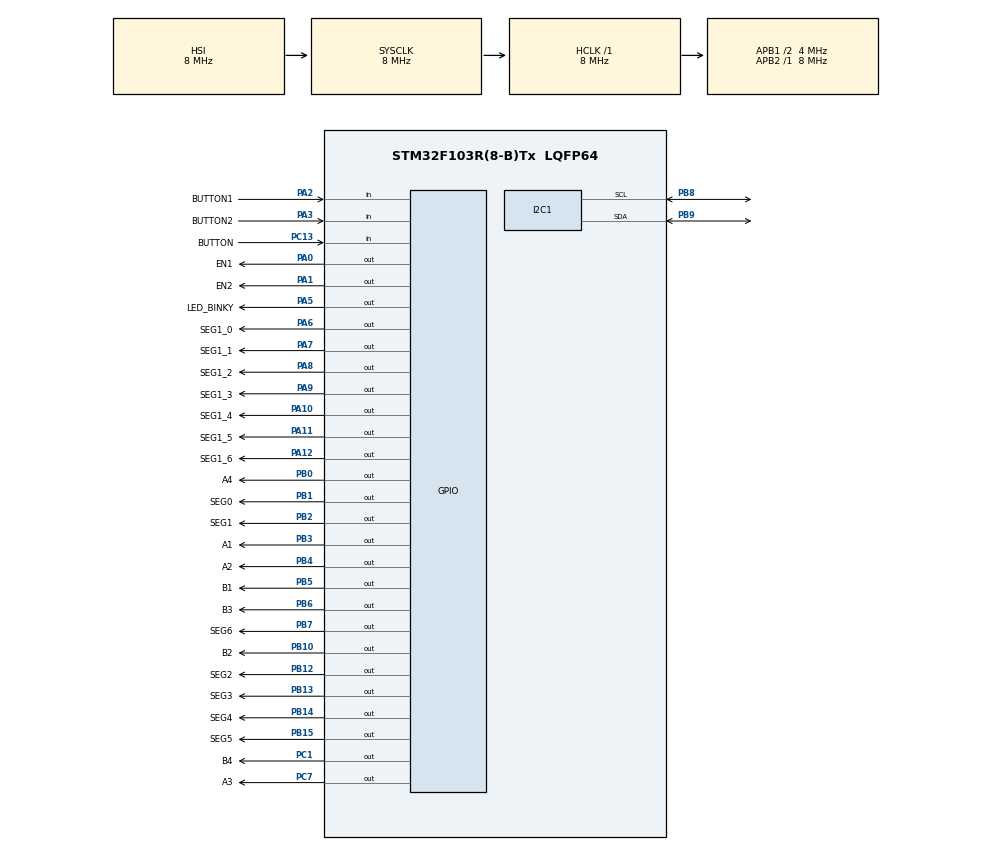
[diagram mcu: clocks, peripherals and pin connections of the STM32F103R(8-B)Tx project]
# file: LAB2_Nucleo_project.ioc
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Mcu.Family=STM32F1
Mcu.Name=STM32F103R(8-B)Tx
Mcu.Package=LQFP64
NVIC.I2C1_ER_IRQn=true\:0\:0\:false\:false\:true\:true\:true
NVIC.I2C1_EV_IRQn=true\:0\:0\:false\:false\:true\:true\:true
NVIC.PriorityGroup=NVIC_PRIORITYGROUP_4
NVIC.TIM2_IRQn=true\:0\:0\:false\:false\:true\:true\:true
PA0-WKUP.GPIO_Label=EN1
PA0-WKUP.Signal=GPIO_Output
PA1.GPIO_Label=EN2
PA1.Signal=GPIO_Output
PA10.GPIO_Label=SEG1_4
PA10.Signal=GPIO_Output
PA11.GPIO_Label=SEG1_5
PA11.Signal=GPIO_Output
PA12.GPIO_Label=SEG1_6
PA12.Signal=GPIO_Output
PA13.Mode=Serial_Wire
PA13.Signal=SYS_JTMS-SWDIO
PA14.Mode=Serial_Wire
PA14.Signal=SYS_JTCK-SWCLK
PA2.GPIO_Label=BUTTON1
PA2.GPIO_PuPd=GPIO_PULLUP
PA2.Signal=GPIO_Input
PA3.GPIO_Label=BUTTON2
PA3.GPIO_PuPd=GPIO_PULLUP
PA3.Signal=GPIO_Input
PA5.GPIO_Label=LED_BINKY
PA5.Signal=GPIO_Output
PA6.GPIO_Label=SEG1_0
PA6.Signal=GPIO_Output
PA7.GPIO_Label=SEG1_1
PA7.Signal=GPIO_Output
PA8.GPIO_Label=SEG1_2
PA8.Signal=GPIO_Output
PA9.GPIO_Label=SEG1_3
PA9.Signal=GPIO_Output
PB0.GPIO_Label=A4
PB0.Signal=GPIO_Output
PB1.GPIO_Label=SEG0
PB1.Signal=GPIO_Output
PB10.GPIO_Label=B2
PB10.Signal=GPIO_Output
PB12.GPIO_Label=SEG2
PB12.Signal=GPIO_Output
PB13.GPIO_Label=SEG3
PB13.Signal=GPIO_Output
PB14.GPIO_Label=SEG4
PB14.Signal=GPIO_Output
PB15.GPIO_Label=SEG5
PB15.Signal=GPIO_Output
PB2.GPIO_Label=SEG1
PB2.Signal=GPIO_Output
PB3.GPIO_Label=A1
PB3.Signal=GPIO_Output
PB4.GPIO_Label=A2
PB4.Signal=GPIO_Output
PB5.GPIO_Label=B1
PB5.Signal=GPIO_Output
PB6.GPIO_Label=B3
PB6.Signal=GPIO_Output
PB7.GPIO_Label=SEG6
PB7.Signal=GPIO_Output
PB8.Mode=I2C
PB8.Signal=I2C1_SCL
PB9.Mode=I2C
PB9.Signal=I2C1_SDA
PC1.GPIO_Label=B4
PC1.Signal=GPIO_Output
PC13-TAMPER-RTC.GPIO_Label=BUTTON
PC13-TAMPER-RTC.GPIO_PuPd=GPIO_PULLUP
PC13-TAMPER-RTC.Signal=GPIO_Input
PC14-OSC32_IN.Mode=LSE-External-Oscillator
PC14-OSC32_IN.Signal=RCC_OSC32_IN
PC15-OSC32_OUT.Mode=LSE-External-Oscillator
PC15-OSC32_OUT.Signal=RCC_OSC32_OUT
PC7.GPIO_Label=A3
PC7.Signal=GPIO_Output
PD0-OSC_IN.Mode=HSE-External-Clock-Source
PD0-OSC_IN.Signal=RCC_OSC_IN
PD1-OSC_OUT.Mode=HSE-External-Clock-Source
PD1-OSC_OUT.Signal=RCC_OSC_OUT
ProjectManager.HeapSize=0x200
ProjectManager.StackSize=0x400
ProjectManager.TargetToolchain=STM32CubeIDE
RCC.AHBFreq_Value=8000000
RCC.APB1CLKDivider=RCC_HCLK_DIV2
RCC.APB1Freq_Value=4000000
RCC.APB1TimFreq_Value=8000000
RCC.APB2Freq_Value=8000000
RCC.APB2TimFreq_Value=8000000
RCC.HCLKFreq_Value=8000000
RCC.PLLMUL=RCC_PLL_MUL16
RCC.RTCClockSelection=RCC_RTCCLKSOURCE_LSE
RCC.SYSCLKFreq_VALUE=8000000
RCC.USBFreq_Value=64000000
TIM2.Period=9
TIM2.Prescaler=7999
VP_TIM2_VS_ClockSourceINT.Mode=Internal
board=NUCLEO-F103RB

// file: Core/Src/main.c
/* USER CODE BEGIN Header */
/**
  ******************************************************************************
  * @file           : main.c
  * @brief          : Main program body
  ******************************************************************************
  * @attention
  *
  * <h2><center>&copy; Copyright (c) 2024 STMicroelectronics.
  * All rights reserved.</center></h2>
  *
  * This software component is licensed by ST under BSD 3-Clause license,
  * the "License"; You may not use this file except in compliance with the
  * License. You may obtain a copy of the License at:
  *                        opensource.org/licenses/BSD-3-Clause
  *
  ******************************************************************************
  */
/* USER CODE END Header */
#include "main.h"

/* USER CODE BEGIN Includes */
#include "global.h"
#include "two_way_traffic.h"
#include "led7.h"
/* USER CODE END Includes */

I2C_HandleTypeDef hi2c1;

TIM_HandleTypeDef htim2;

void SystemClock_Config(void);
static void MX_GPIO_Init(void);
static void MX_TIM2_Init(void);
static void MX_I2C1_Init(void);

/* USER CODE BEGIN 0 */
GPIO_TypeDef* GPIOx[3] = {BUTTON_GPIO_Port,BUTTON1_GPIO_Port,BUTTON2_GPIO_Port};
uint16_t GPIO_Pin[3] = {BUTTON_Pin,BUTTON1_Pin,BUTTON2_Pin};
/* USER CODE END 0 */

int main(void)
{

  /* MCU Configuration--------------------------------------------------------*/

  /* Reset of all peripherals, Initializes the Flash interface and the Systick. */
  HAL_Init();

  /* Configure the system clock */
  SystemClock_Config();

  /* Initialize all configured peripherals */
  MX_GPIO_Init();
  MX_TIM2_Init();
  MX_I2C1_Init();
  /* USER CODE BEGIN 2 */
  HAL_TIM_Base_Start_IT(&htim2);
	two_way_traffic_init();
  /* USER CODE END 2 */

  /* Infinite loop */
  /* USER CODE BEGIN WHILE */
  while (1)
  {
	  two_way_traffic_run();

    /* USER CODE END WHILE */

  }
}

void SystemClock_Config(void)
{
  RCC_OscInitTypeDef RCC_OscInitStruct = {0};
  RCC_ClkInitTypeDef RCC_ClkInitStruct = {0};

  /** Initializes the RCC Oscillators according to the specified parameters
  * in the RCC_OscInitTypeDef structure.
  */
  RCC_OscInitStruct.OscillatorType = RCC_OSCILLATORTYPE_HSI;
  RCC_OscInitStruct.HSIState = RCC_HSI_ON;
  RCC_OscInitStruct.HSICalibrationValue = RCC_HSICALIBRATION_DEFAULT;
  RCC_OscInitStruct.PLL.PLLState = RCC_PLL_NONE;
  if (HAL_RCC_OscConfig(&RCC_OscInitStruct) != HAL_OK)
  {
    Error_Handler();
  }
  /** Initializes the CPU, AHB and APB buses clocks
  */
  RCC_ClkInitStruct.ClockType = RCC_CLOCKTYPE_HCLK|RCC_CLOCKTYPE_SYSCLK
                              |RCC_CLOCKTYPE_PCLK1|RCC_CLOCKTYPE_PCLK2;
  RCC_ClkInitStruct.SYSCLKSource = RCC_SYSCLKSOURCE_HSI;
  RCC_ClkInitStruct.AHBCLKDivider = RCC_SYSCLK_DIV1;
  RCC_ClkInitStruct.APB1CLKDivider = RCC_HCLK_DIV2;
  RCC_ClkInitStruct.APB2CLKDivider = RCC_HCLK_DIV1;

  if (HAL_RCC_ClockConfig(&RCC_ClkInitStruct, FLASH_LATENCY_0) != HAL_OK)
  {
    Error_Handler();
  }
}

static void MX_I2C1_Init(void)
{

  hi2c1.Instance = I2C1;
  hi2c1.Init.ClockSpeed = 100000;
  hi2c1.Init.DutyCycle = I2C_DUTYCYCLE_2;
  hi2c1.Init.OwnAddress1 = 0;
  hi2c1.Init.AddressingMode = I2C_ADDRESSINGMODE_7BIT;
  hi2c1.Init.DualAddressMode = I2C_DUALADDRESS_DISABLE;
  hi2c1.Init.OwnAddress2 = 0;
  hi2c1.Init.GeneralCallMode = I2C_GENERALCALL_DISABLE;
  hi2c1.Init.NoStretchMode = I2C_NOSTRETCH_DISABLE;
  if (HAL_I2C_Init(&hi2c1) != HAL_OK)
  {
    Error_Handler();
  }

}

static void MX_TIM2_Init(void)
{

  TIM_ClockConfigTypeDef sClockSourceConfig = {0};
  TIM_MasterConfigTypeDef sMasterConfig = {0};

  htim2.Instance = TIM2;
  htim2.Init.Prescaler = 7999;
  htim2.Init.CounterMode = TIM_COUNTERMODE_UP;
  htim2.Init.Period = 9;
  htim2.Init.ClockDivision = TIM_CLOCKDIVISION_DIV1;
  htim2.Init.AutoReloadPreload = TIM_AUTORELOAD_PRELOAD_DISABLE;
  if (HAL_TIM_Base_Init(&htim2) != HAL_OK)
  {
    Error_Handler();
  }
  sClockSourceConfig.ClockSource = TIM_CLOCKSOURCE_INTERNAL;
  if (HAL_TIM_ConfigClockSource(&htim2, &sClockSourceConfig) != HAL_OK)
  {
    Error_Handler();
  }
  sMasterConfig.MasterOutputTrigger = TIM_TRGO_RESET;
  sMasterConfig.MasterSlaveMode = TIM_MASTERSLAVEMODE_DISABLE;
  if (HAL_TIMEx_MasterConfigSynchronization(&htim2, &sMasterConfig) != HAL_OK)
  {
    Error_Handler();
  }

}

static void MX_GPIO_Init(void)
{
  GPIO_InitTypeDef GPIO_InitStruct = {0};

  /* GPIO Ports Clock Enable */
  __HAL_RCC_GPIOC_CLK_ENABLE();
  __HAL_RCC_GPIOD_CLK_ENABLE();
  __HAL_RCC_GPIOA_CLK_ENABLE();
  __HAL_RCC_GPIOB_CLK_ENABLE();

  /*Configure GPIO pin Output Level */
  HAL_GPIO_WritePin(GPIOC, B4_Pin|A3_Pin, GPIO_PIN_RESET);

  /*Configure GPIO pin Output Level */
  HAL_GPIO_WritePin(GPIOA, EN1_Pin|EN2_Pin|LED_BINKY_Pin|SEG1_0_Pin
                          |SEG1_1_Pin|SEG1_2_Pin|SEG1_3_Pin|SEG1_4_Pin
                          |SEG1_5_Pin|SEG1_6_Pin, GPIO_PIN_RESET);

  /*Configure GPIO pin Output Level */
  HAL_GPIO_WritePin(GPIOB, A4_Pin|SEG0_Pin|SEG1_Pin|B2_Pin
                          |SEG2_Pin|SEG3_Pin|SEG4_Pin|SEG5_Pin
                          |A1_Pin|A2_Pin|B1_Pin|B3_Pin
                          |SEG6_Pin, GPIO_PIN_RESET);

  /*Configure GPIO pin : BUTTON_Pin */
  GPIO_InitStruct.Pin = BUTTON_Pin;
  GPIO_InitStruct.Mode = GPIO_MODE_INPUT;
  GPIO_InitStruct.Pull = GPIO_PULLUP;
  HAL_GPIO_Init(BUTTON_GPIO_Port, &GPIO_InitStruct);

  /*Configure GPIO pins : B4_Pin A3_Pin */
  GPIO_InitStruct.Pin = B4_Pin|A3_Pin;
  GPIO_InitStruct.Mode = GPIO_MODE_OUTPUT_PP;
  GPIO_InitStruct.Pull = GPIO_NOPULL;
  GPIO_InitStruct.Speed = GPIO_SPEED_FREQ_LOW;
  HAL_GPIO_Init(GPIOC, &GPIO_InitStruct);

  /*Configure GPIO pins : EN1_Pin EN2_Pin LED_BINKY_Pin SEG1_0_Pin
                           SEG1_1_Pin SEG1_2_Pin SEG1_3_Pin SEG1_4_Pin
                           SEG1_5_Pin SEG1_6_Pin */
  GPIO_InitStruct.Pin = EN1_Pin|EN2_Pin|LED_BINKY_Pin|SEG1_0_Pin
                          |SEG1_1_Pin|SEG1_2_Pin|SEG1_3_Pin|SEG1_4_Pin
                          |SEG1_5_Pin|SEG1_6_Pin;
  GPIO_InitStruct.Mode = GPIO_MODE_OUTPUT_PP;
  GPIO_InitStruct.Pull = GPIO_NOPULL;
  GPIO_InitStruct.Speed = GPIO_SPEED_FREQ_LOW;
  HAL_GPIO_Init(GPIOA, &GPIO_InitStruct);

  /*Configure GPIO pins : BUTTON1_Pin BUTTON2_Pin */
  GPIO_InitStruct.Pin = BUTTON1_Pin|BUTTON2_Pin;
  GPIO_InitStruct.Mode = GPIO_MODE_INPUT;
  GPIO_InitStruct.Pull = GPIO_PULLUP;
  HAL_GPIO_Init(GPIOA, &GPIO_InitStruct);

  /*Configure GPIO pins : A4_Pin SEG0_Pin SEG1_Pin B2_Pin
                           SEG2_Pin SEG3_Pin SEG4_Pin SEG5_Pin
                           A1_Pin A2_Pin B1_Pin B3_Pin
                           SEG6_Pin */
  GPIO_InitStruct.Pin = A4_Pin|SEG0_Pin|SEG1_Pin|B2_Pin
                          |SEG2_Pin|SEG3_Pin|SEG4_Pin|SEG5_Pin
                          |A1_Pin|A2_Pin|B1_Pin|B3_Pin
                          |SEG6_Pin;
  GPIO_InitStruct.Mode = GPIO_MODE_OUTPUT_PP;
  GPIO_InitStruct.Pull = GPIO_NOPULL;
  GPIO_InitStruct.Speed = GPIO_SPEED_FREQ_LOW;
  HAL_GPIO_Init(GPIOB, &GPIO_InitStruct);

}

/* USER CODE BEGIN 4 */
void HAL_TIM_PeriodElapsedCallback(TIM_HandleTypeDef *htim){
	timerRun();
	button_reading(GPIOx, GPIO_Pin);
}
/* USER CODE END 4 */

void Error_Handler(void)
{
  __disable_irq();
  while (1)
  {
  }
}

/************************ (C) COPYRIGHT STMicroelectronics *****END OF FILE****/
